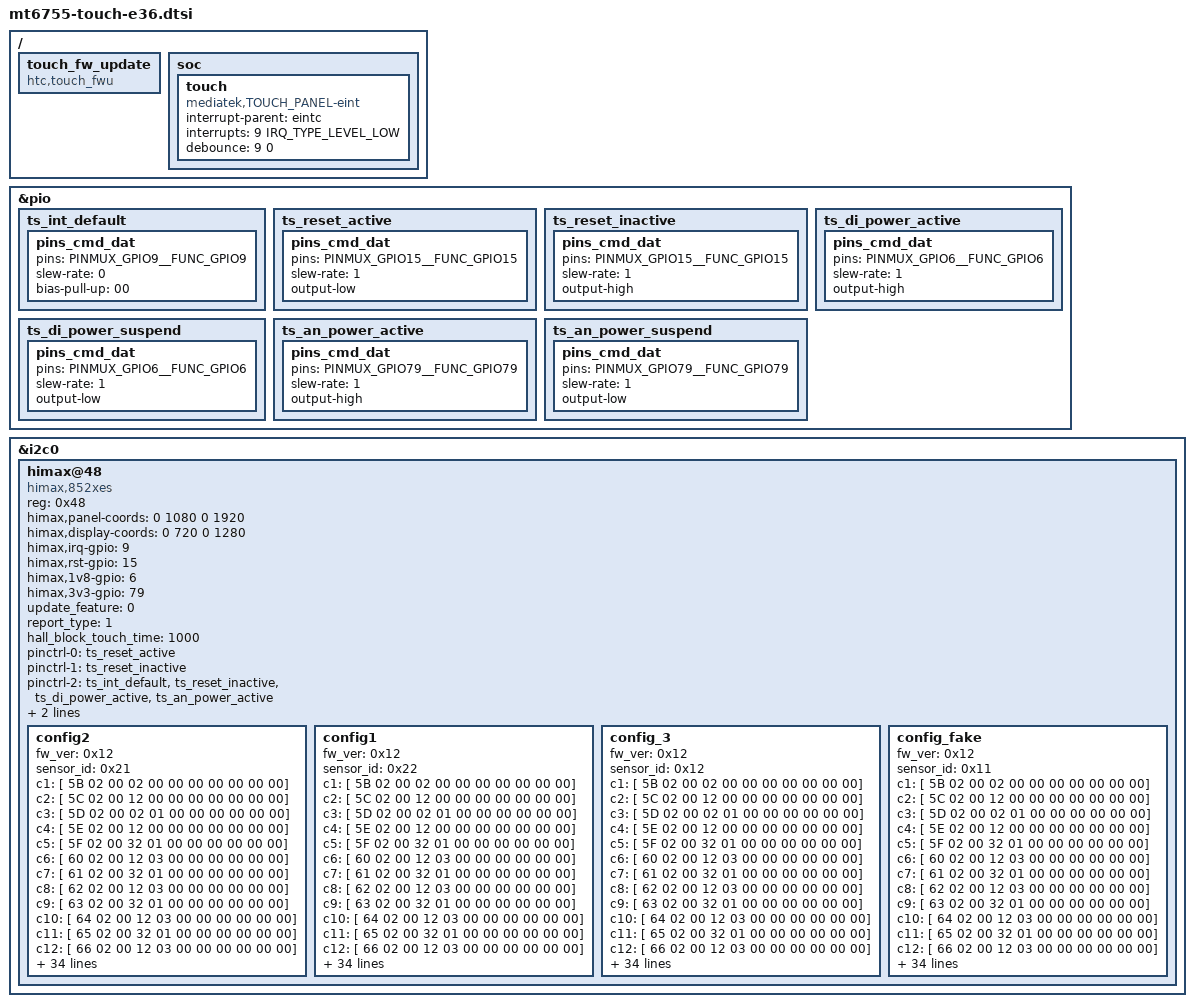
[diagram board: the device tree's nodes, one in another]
/ {
	touch_fw_update {
		compatible = "htc,touch_fwu";
	};

	soc {
		touch {
			compatible = "mediatek,TOUCH_PANEL-eint";
			interrupt-parent = <&eintc>;
			interrupts = <9 IRQ_TYPE_LEVEL_LOW>;
			debounce = <9 0>;
			status = "okay";
		};
	};
};

&pio {
	ts_int_default: ts_int_default {
		pins_cmd_dat {
			pins = <PINMUX_GPIO9__FUNC_GPIO9>;
			slew-rate = <0>;	/* INPUT */
			bias-pull-up = <00>;
		};
	};

	ts_reset_active: ts_reset_active {
		pins_cmd_dat {
			pins = <PINMUX_GPIO15__FUNC_GPIO15>;
			slew-rate = <1>;	/* OUTPUT */
			output-low;
		};
	};
	ts_reset_inactive: ts_reset_inactive {
		pins_cmd_dat {
			pins = <PINMUX_GPIO15__FUNC_GPIO15>;
			slew-rate = <1>;	/* OUTPUT */
			output-high;
		};
	};

	ts_di_power_active: ts_di_power_active {
		pins_cmd_dat {
			pins = <PINMUX_GPIO6__FUNC_GPIO6>;
			slew-rate = <1>;	/* OUTPUT */
			output-high;
		};
	};

	ts_di_power_suspend: ts_di_power_suspend {
		pins_cmd_dat {
			pins = <PINMUX_GPIO6__FUNC_GPIO6>;
			slew-rate = <1>;	/* OUTPUT */
			output-low;
		};
	};

	ts_an_power_active: ts_an_power_active {
		pins_cmd_dat {
			pins = <PINMUX_GPIO79__FUNC_GPIO79>;
			slew-rate = <1>;	/* OUTPUT */
			output-high;
		};
	};

	ts_an_power_suspend: ts_an_power_suspend {
		pins_cmd_dat {
			pins = <PINMUX_GPIO79__FUNC_GPIO79>;
			slew-rate = <1>;	/* OUTPUT */
			output-low;
		};
	};
};

&i2c0 {
	himax@48 {
		compatible		= "himax,852xes";
		reg			= <0x48>;
		status			= "okay";
		himax,panel-coords	= <0 1080 0 1920>;
		himax,display-coords	= <0 720 0 1280>;
		himax,irq-gpio		= <9>;
		himax,rst-gpio		= <15>;
		himax,1v8-gpio		= <6>;
		himax,3v3-gpio		= <79>;
		update_feature		= <0>;
		report_type		= <1>;
		hall_block_touch_time	= <1000>;	/* msec */
		pinctrl-names = "pmx_ts_reset_active", "pmx_ts_reset_inactive",
				"pmx_ts_active", "pmx_ts_suspend";
		pinctrl-0 = <&ts_reset_active>;
		pinctrl-1 = <&ts_reset_inactive>;
		pinctrl-2 = <&ts_int_default &ts_reset_inactive &ts_di_power_active &ts_an_power_active>;
		pinctrl-3 = <&ts_int_default &ts_reset_inactive &ts_di_power_suspend &ts_an_power_suspend>;

		config2 {	//Tianma, main
			fw_ver		= <0x12>;
			sensor_id	= <0x21>;
//FIXME			cover_support;
			c1 =[ 5B 02 00 02 00 00 00 00 00 00 00];
			c2 =[ 5C 02 00 12 00 00 00 00 00 00 00];
			c3 =[ 5D 02 00 02 01 00 00 00 00 00 00];
			c4 =[ 5E 02 00 12 00 00 00 00 00 00 00];
			c5 =[ 5F 02 00 32 01 00 00 00 00 00 00];
			c6 =[ 60 02 00 12 03 00 00 00 00 00 00];
			c7 =[ 61 02 00 32 01 00 00 00 00 00 00];
			c8 =[ 62 02 00 12 03 00 00 00 00 00 00];
			c9 =[ 63 02 00 32 01 00 00 00 00 00 00];
			c10 = [ 64 02 00 12 03 00 00 00 00 00 00];
			c11 = [ 65 02 00 32 01 00 00 00 00 00 00];
			c12 = [ 66 02 00 12 03 00 00 00 00 00 00];
			c13 = [ 67 00 00 30 01 00 00 00 00 00 00];
			c14 = [ 68 00 00 00 00 00 00 00 00 00 00];
			c15 = [ 69 00 00 00 00 00 00 00 00 00 00];
			c16 = [ 6A 00 00 20 00 00 00 00 00 00 00];
			c17 = [ 6B 01 00 01 02 00 00 00 00 00 00];
			c18 = [ D5 29 00 00 00 00 00 00 00 00 00
				00 00 00 00 00 00];
			c19 = [ E1 07 01 02 02 02 03 07 03 0F 03 0F 02 0F 08]; //
			c20 = [ BC 08 00 00 00]; //
			c21 = [ C5 0A 1F 00 10 18 1A 0B 1F 02 1F]; //Self Setting
			c22 = [C6 18 10 1D]; //Mutual Setting
			c23 = [ BD 00 0B]; //SETCLK12
			c24 = [ B9 01 05]; //SET CVDD
			c25 = [ EC 10 9E 8D]; //SET PTBA
			c26 = [ B0 00]; //TX Floating
			c27 = [ DD 03]; //Set Cache
			c28 = [ 42 02]; //Reload Disable
			c29 = [ CE 00]; //HW Watch Dog
			c30 = [ CA 00]; //ESD Detector
			c31 = [ 3F 00]; //Dual Mode
			c32 = [ EB 03]; //SET AP
			c33 = [ BA 00]; //SET EQ
			c34 = [ BB 00]; //D0200 added.
			c35 = [ D3 06 01]; //TX Pumping Postivite
			c36 = [ 37 FF 08 FF 08]; //POWRSTB
			c37 = [ A4 94 62 94 86]; //Dual Mode
			c38 = [ ED 00 04 0A 0A 04 00 00 00]; //SET CLK
			c39 = [ CB 00 0F 0F FF FF 01 00 0F 00 32
				00 FF 00]; //GPIO_EN
			c40 = [ 40 01 5A //Customer Info
				5F 00 F0 10 44 00 //Switch
				1C 0A 0C 10 09 09 09 0F 0F 0F //Threshold
				38 30 40 40 40 24 A6 05 00 00 00 00 //Weighting
				94 0A F0 11 44 00 //Stability
				44 22 0F 0F 83 3C 00 00 //Palm
				11 00 41 42 //Enter
				18 58 00 12 00 00 //CCL
				08 01 3C 64 00 00 //Timer
				18 37 37 05 1F 02 00 00 //OSR Hopping
				04 06 24 07 07 00 00 00 //TX Hopping
				3F 40 0A 54 00 D8 8C 20 00 02
				03 10 00 00 00 00 //Idle
				10 02 80 00 00 00 00 0C //Water
				10 00 20 18 03 07 0B 00 //MKey
				C8 78 28 00 //Bank
				0D 17 A0 13 //Channel
				00 00 02 D0 05 00 //Resolution
				05 FE 0D 7C 66 11 08 00 BC 03 06 5B DC 0A //Fitting Curve 1
				07 93 11 0A 6A F5 00 01 0E 04 58 5F 31 00 //Fitting Curve 2
				00 01 00 00 00 00 00 00]; //OLM Gen1 Pattern
			c41 = [ 40 FF 0D 0E 0F 10 11 12 13 14 15 //Channel 01~17
				16 17 18 FF FF FF 00
				01 02 03 04 05 06 07 08 09 0A //Channel 18~34
				0B 0C FF FF FF 23 22
				FF FF FF FF 21 20 1F 1E 1D 1C //Channel 35~51
				1B 1A 19 FF FF FF FF
				FF FF FF	//Channel 52~54
				00 00 00 00 00 00 //Noise Matrix
				00 00 00 00 00 00 //Reserve
				00 00 00 00 00 00 //Reserve
				00 8F 00 00 00 00 00 00 //Sensor Hub Gesture for HTC
				11 C4 45 C5 48 5C 03 55 00 00 //High Sensitivity Mode
				00 00 00 00 00 00 //Reserve
				00 00]; //Checksum
		};

		config1 {	//Truly
			fw_ver		= <0x12>;
			sensor_id	= <0x22>;
//FIXME			cover_support;
			c1 =[ 5B 02 00 02 00 00 00 00 00 00 00];
			c2 =[ 5C 02 00 12 00 00 00 00 00 00 00];
			c3 =[ 5D 02 00 02 01 00 00 00 00 00 00];
			c4 =[ 5E 02 00 12 00 00 00 00 00 00 00];
			c5 =[ 5F 02 00 32 01 00 00 00 00 00 00];
			c6 =[ 60 02 00 12 03 00 00 00 00 00 00];
			c7 =[ 61 02 00 32 01 00 00 00 00 00 00];
			c8 =[ 62 02 00 12 03 00 00 00 00 00 00];
			c9 =[ 63 02 00 32 01 00 00 00 00 00 00];
			c10 = [ 64 02 00 12 03 00 00 00 00 00 00];
			c11 = [ 65 02 00 32 01 00 00 00 00 00 00];
			c12 = [ 66 02 00 12 03 00 00 00 00 00 00];
			c13 = [ 67 00 00 30 01 00 00 00 00 00 00];
			c14 = [ 68 00 00 00 00 00 00 00 00 00 00];
			c15 = [ 69 00 00 00 00 00 00 00 00 00 00];
			c16 = [ 6A 00 00 20 00 00 00 00 00 00 00];
			c17 = [ 6B 01 00 01 02 00 00 00 00 00 00];
			c18 = [ D5 29 00 00 00 00 00 00 00 00 00
				00 00 00 00 00 00];
			c19 = [ E1 07 01 02 02 02 03 07 03 0F 03 0F 02 0F 08]; //
			c20 = [ BC 08 00 00 00]; //
			c21 = [ C5 0A 1F 00 10 18 1A 0B 1F 02 1F]; //Self Setting
			c22 = [ C6 18 10 19]; //Mutual Setting
			c23 = [ BD 00 0B]; //SETCLK12
			c24 = [ B9 01 05]; //SET CVDD
			c25 = [ EC 10 9E 8D]; //SET PTBA
			c26 = [ B0 00]; //TX Floating
			c27 = [ DD 03]; //Set Cache
			c28 = [ 42 02]; //Reload Disable
			c29 = [ CE 00]; //HW Watch Dog
			c30 = [ CA 00]; //ESD Detector
			c31 = [ 3F 00]; //Dual Mode
			c32 = [ EB 03]; //SET AP
			c33 = [ BA 00]; //SET EQ
			c34 = [ BB 00]; //D0200 added.
			c35 = [ D3 06 01]; //TX Pumping Postivite
			c36 = [ 37 FF 08 FF 08]; //POWRSTB
			c37 = [ A4 94 62 94 86]; //Dual Mode
			c38 = [ ED 00 04 0A 0A 04 00 00 00]; //SET CLK
			c39 = [ CB 00 0F 0F FF FF 01 00 0F 00 32
				00 FF 00]; //GPIO_EN
			c40 = [ 40 03 5A //Customer Info
				5F 00 F0 10 04 00 //Switch
				1C 0A 0C 10 09 09 09 0F 0F 0F //Threshold
				20 20 30 30 40 3C A6 05 00 00 00 00 //Weighting
				94 0A F0 11 44 00 //Stability
				44 24 0F 0F 83 3C 00 00 //Palm
				11 00 41 42 //Enter
				1F 5F 00 12 00 00 //CCL
				08 01 3C 64 00 00 //Timer
				18 37 37 05 1F 02 00 00 //OSR Hopping
				04 06 24 07 07 00 00 00 //TX Hopping
				3F 40 0A 54 00 D8 8C 20 00 02
				03 10 00 00 00 00 //Idle
				10 02 80 00 00 00 00 0C //Water
				10 00 20 18 03 07 0B 00 //MKey
				C8 78 28 00 //Bank
				0D 17 A0 13 //Channel
				00 00 02 D0 05 00 //Resolution
				05 FE 0D 7C 66 11 08 00 BC 03 06 5B DC 0A //Fitting Curve 1
				07 93 11 0A 6A F5 00 01 0E 04 58 5F 31 00 //Fitting Curve 2
				00 01 00 00 00 00 00 00]; //OLM Gen1 Pattern
			c41 = [ 40 FF 0D 0E 0F 10 11 12 13 14 15 //Channel 01~17
				16 17 18 FF FF FF 00
				01 02 03 04 05 06 07 08 09 0A //Channel 18~34
				0B 0C FF FF FF 23 22
				FF FF FF FF 21 20 1F 1E 1D 1C //Channel 35~51
				1B 1A 19 FF FF FF FF
				FF FF FF	//Channel 52~54
				00 00 00 00 00 00 //Noise Matrix
				00 00 00 00 00 00 //Reserve
				00 00 00 00 00 00 //Reserve
				00 8F 00 00 00 00 00 00 //Sensor Hub Gesture for HTC
				11 C4 45 C5 48 5C 03 55 00 00 //High Sensitivity Mode
				00 00 00 00 00 00 //Reserve
				00 00]; //Checksum
		};

		config_3 {	//Reserved
			fw_ver		= <0x12>;
			sensor_id	= <0x12>;
//FIXME			cover_support;
			c1 =[ 5B 02 00 02 00 00 00 00 00 00 00];
			c2 =[ 5C 02 00 12 00 00 00 00 00 00 00];
			c3 =[ 5D 02 00 02 01 00 00 00 00 00 00];
			c4 =[ 5E 02 00 12 00 00 00 00 00 00 00];
			c5 =[ 5F 02 00 32 01 00 00 00 00 00 00];
			c6 =[ 60 02 00 12 03 00 00 00 00 00 00];
			c7 =[ 61 02 00 32 01 00 00 00 00 00 00];
			c8 =[ 62 02 00 12 03 00 00 00 00 00 00];
			c9 =[ 63 02 00 32 01 00 00 00 00 00 00];
			c10 = [ 64 02 00 12 03 00 00 00 00 00 00];
			c11 = [ 65 02 00 32 01 00 00 00 00 00 00];
			c12 = [ 66 02 00 12 03 00 00 00 00 00 00];
			c13 = [ 67 00 00 30 01 00 00 00 00 00 00];
			c14 = [ 68 00 00 00 00 00 00 00 00 00 00];
			c15 = [ 69 00 00 00 00 00 00 00 00 00 00];
			c16 = [ 6A 00 00 20 00 00 00 00 00 00 00];
			c17 = [ 6B 01 00 01 02 00 00 00 00 00 00];
			c18 = [ D5 29 00 00 00 00 00 00 00 00 00
				00 00 00 00 00 00];
			c19 = [ E1 07 01 02 02 02 03 07 03 0F 03 0F 02 0F 08]; //
			c20 = [ BC 08 00 00 00]; //
			c21 = [ C5 0A 1F 00 10 18 1A 0B 1F 02 1F]; //Self Setting
			c22 = [ C6 18 10 19]; //Mutual Setting
			c23 = [ BD 00 0B]; //SETCLK12
			c24 = [ B9 01 05]; //SET CVDD
			c25 = [ EC 10 9E 8D]; //SET PTBA
			c26 = [ B0 00]; //TX Floating
			c27 = [ DD 03]; //Set Cache
			c28 = [ 42 02]; //Reload Disable
			c29 = [ CE 00]; //HW Watch Dog
			c30 = [ CA 00]; //ESD Detector
			c31 = [ 3F 00]; //Dual Mode
			c32 = [ EB 03]; //SET AP
			c33 = [ BA 00]; //SET EQ
			c34 = [ BB 00]; //D0200 added.
			c35 = [ D3 06 01]; //TX Pumping Postivite
			c36 = [ 37 FF 08 FF 08]; //POWRSTB
			c37 = [ A4 94 62 94 86]; //Dual Mode
			c38 = [ ED 00 04 0A 0A 04 00 00 00]; //SET CLK
			c39 = [ CB 00 0F 0F FF FF 01 00 0F 00 32
				00 FF 00]; //GPIO_EN
			c40 = [ 40 03 5A //Customer Info
				5F 00 F0 10 04 00 //Switch
				1C 0A 0C 10 09 09 09 0F 0F 0F //Threshold
				20 20 30 30 40 3C A6 05 00 00 00 00 //Weighting
				94 0A F0 11 44 00 //Stability
				44 24 0F 0F 83 3C 00 00 //Palm
				11 00 41 42 //Enter
				1F 5F 00 12 00 00 //CCL
				08 01 3C 64 00 00 //Timer
				18 37 37 05 1F 02 00 00 //OSR Hopping
				04 06 24 07 07 00 00 00 //TX Hopping
				3F 40 0A 54 00 D8 8C 20 00 02
				03 10 00 00 00 00 //Idle
				10 02 80 00 00 00 00 0C //Water
				10 00 20 18 03 07 0B 00 //MKey
				C8 78 28 00 //Bank
				0D 17 A0 13 //Channel
				00 00 02 D0 05 00 //Resolution
				05 FE 0D 7C 66 11 08 00 BC 03 06 5B DC 0A //Fitting Curve 1
				07 93 11 0A 6A F5 00 01 0E 04 58 5F 31 00 //Fitting Curve 2
				00 01 00 00 00 00 00 00]; //OLM Gen1 Pattern
			c41 = [ 40 FF 0D 0E 0F 10 11 12 13 14 15 //Channel 01~17
				16 17 18 FF FF FF 00
				01 02 03 04 05 06 07 08 09 0A //Channel 18~34
				0B 0C FF FF FF 23 22
				FF FF FF FF 21 20 1F 1E 1D 1C //Channel 35~51
				1B 1A 19 FF FF FF FF
				FF FF FF	//Channel 52~54
				00 00 00 00 00 00 //Noise Matrix
				00 00 00 00 00 00 //Reserve
				00 00 00 00 00 00 //Reserve
				00 8F 00 00 00 00 00 00 //Sensor Hub Gesture for HTC
				11 C4 45 C5 48 5C 03 55 00 00 //High Sensitivity Mode
				00 00 00 00 00 00 //Reserve
				00 00]; //Checksum
		};

		config_fake {	//semi Truly GFF
			fw_ver		= <0x12>;
			sensor_id	= <0x11>;
			c1 =  [ 5B 02 00 02 00 00 00 00 00 00 00];
			c2 =  [ 5C 02 00 12 00 00 00 00 00 00 00];
			c3 =  [ 5D 02 00 02 01 00 00 00 00 00 00];
			c4 =  [ 5E 02 00 12 00 00 00 00 00 00 00];
			c5 =  [ 5F 02 00 32 01 00 00 00 00 00 00];
			c6 =  [ 60 02 00 12 03 00 00 00 00 00 00];
			c7 =  [ 61 02 00 32 01 00 00 00 00 00 00];
			c8 =  [ 62 02 00 12 03 00 00 00 00 00 00];
			c9 =  [ 63 02 00 32 01 00 00 00 00 00 00];
			c10 = [ 64 02 00 12 03 00 00 00 00 00 00];
			c11 = [ 65 02 00 32 01 00 00 00 00 00 00];
			c12 = [ 66 02 00 12 03 00 00 00 00 00 00];
			c13 = [ 67 00 00 30 01 00 00 00 00 00 00];
			c14 = [ 68 00 00 00 00 00 00 00 00 00 00];
			c15 = [ 69 00 00 00 00 00 00 00 00 00 00];
			c16 = [ 6A 00 00 20 00 00 00 00 00 00 00];
			c17 = [ 6B 01 00 01 02 00 00 00 00 00 00];
			c18 = [ D5 29 00 00 00 00 00 00 00 00 00
				00 00 00 00 00 00];
			c19 = [ E1 07 01 02 02 02 03 07 03 0F 03 0F 02 0F 08];
			c20 = [ BC 08 00 00 00];
			c21 = [ C5 0A 1F 00 10 18 1A 0B 1F 02 1F]; //Self Setting
			c22 = [ C6 18 10 1C]; //Mutual Setting
			c23 = [ BD 00 0B]; //SETCLK12
			c24 = [ B9 01 05]; //SET CVDD
			c25 = [ EC 10 9E 8D]; //SET PTBA
			c26 = [ B0 00]; //TX Floating
			c27 = [ DD 03]; //Set Cache
			c28 = [ 42 02]; //Reload Disable
			c29 = [ CE 00]; //HW Watch Dog
			c30 = [ CA 00]; //ESD Detector
			c31 = [ 3F 00]; //Dual Mode
			c32 = [ EB 03]; //SET AP
			c33 = [ BA 00]; //SET EQ
			c34 = [ BB 00]; //D0200 added
			c35 = [ D3 06 01]; //TX Pumping Postivite
			c36 = [ 37 FF 08 FF 08]; //POWRSTB
			c37 = [ A4 94 62 94 86]; //Dual Mode
			c38 = [ ED 00 04 0A 0A 04 00 00 00]; //SET CLK
			c39 = [ CB 00 0F 0F FF FF 01 00 0F 00 32
				00 FF 00]; //GPIO_EN
			c40 = [ 40 04 5A                         //Customer Info
				5F 00 F0 10 44 00                //Switch
				1C 0C 0B 0C 09 09 09 0F 0F 0F    //Threshold
				38 30 40 40 30 00 00 00 00 00 00 00 //Weighting
				94 0A F0 11 44 00                //Stability
				44 22 0F 0F 83 3C 00 00          //Palm
				11 00 41 42                      //Enter
				18 48 00 12 00 00                //CCL
				08 01 3C 64 00 00                //Timer
				18 37 37 05 1F 02 00 00          //OSR Hopping
				04 06 24 07 07 00 00 00          //TX Hopping
				3D 40 0A 54 00 D8 8C 20 00 02
				03 10 00 00 00 00                //Idle
				10 02 80 00 00 00 00 0C          //Water
				10 00 20 18 03 07 0B 00          //MKey
				C8 78 28 00                      //Bank
				0D 17 A0 13                      //Channel
				00 00 02 D0 05 00                //Resolution
				05 FE 0D 7C 66 11 08 00 BC 03 06 5B DC 0A //Fitting Curve 1
				07 93 11 0A 6A F5 00 01 0E 04 58 5F 31 00 //Fitting Curve 2
				00 00 00 00 00 00 00 00];        //OLM Gen1 Pattern
			c41 = [ 40 FF 0D 0E 0F 10 11 12 13 14 15 //Channel 01~17
				16 17 18 FF FF FF 00
				01 02 03 04 05 06 07 08 09 0A 	 //Channel 18~34
				0B 0C FF FF FF 23 22
				FF FF FF FF 21 20 1F 1E 1D 1C    //Channel 35~51
				1B 1A 19 FF FF FF FF
				FF FF FF                         //Channel 52~54
				00 00 00 00 00 00                //Noise Matrix
				00 00 00 00 00 00                //Reserve
				00 00 00 00 00 00                //Reserve
				00 8F 00 00 00 00 00 00          //Sensor Hub Gesture for HTC
				11 C4 45 C5 48 5C 03 55 00 00    //High Sensitivity Mode
				00 00 00 00 00 00 //Reserve
				00 00]; //Checksum
		};
	};
};
